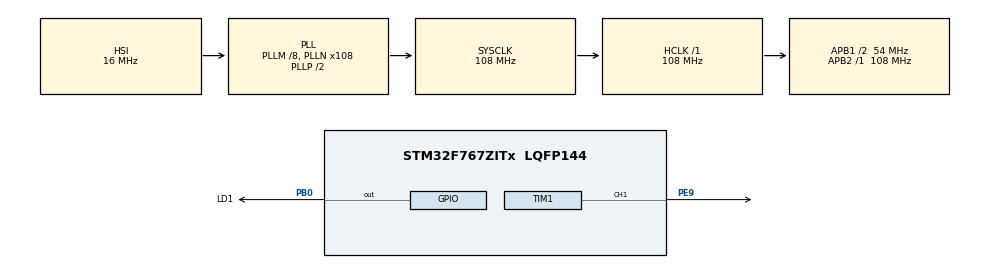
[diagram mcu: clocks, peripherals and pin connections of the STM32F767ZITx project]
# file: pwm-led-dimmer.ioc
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Mcu.Family=STM32F7
Mcu.Name=STM32F767ZITx
Mcu.Package=LQFP144
NVIC.PriorityGroup=NVIC_PRIORITYGROUP_4
PB0.GPIO_Label=LD1
PB0.Signal=GPIO_Output
PE9.Signal=S_TIM1_CH1
PH0/OSC_IN.Mode=HSE-External-Oscillator
PH0/OSC_IN.Signal=RCC_OSC_IN
PH1/OSC_OUT.Mode=HSE-External-Oscillator
PH1/OSC_OUT.Signal=RCC_OSC_OUT
ProjectManager.HeapSize=0x200
ProjectManager.StackSize=0x400
ProjectManager.TargetToolchain=STM32CubeIDE
RCC.48MHZClocksFreq_Value=24000000
RCC.AHBFreq_Value=108000000
RCC.APB1CLKDivider=RCC_HCLK_DIV2
RCC.APB1Freq_Value=54000000
RCC.APB1TimFreq_Value=108000000
RCC.APB2Freq_Value=108000000
RCC.APB2TimFreq_Value=108000000
RCC.CortexFreq_Value=108000000
RCC.HCLKFreq_Value=108000000
RCC.HSE_VALUE=8000000
RCC.HSI_VALUE=16000000
RCC.LSE_VALUE=32768
RCC.PLLM=8
RCC.PLLMUL=RCC_PLL_MUL9
RCC.PLLN=108
RCC.PRESCALERUSB=RCC_USBCLKSOURCE_PLL_DIV1_5
RCC.SYSCLKFreq_VALUE=108000000
RCC.SYSCLKSource=RCC_SYSCLKSOURCE_PLLCLK
RCC.SYSCLKSourceVirtual=RCC_SYSCLKSOURCE_PLLCLK
RCC.USBFreq_Value=108000000
RCC.VCOOutputFreq_Value=216000000
SH.S_TIM1_CH1.0=TIM1_CH1,PWM Generation1 CH1
TIM1.Channel-PWM\ Generation1\ CH1=TIM_CHANNEL_1
TIM1.Period=999
TIM1.Prescaler=108-1
VP_TIM1_VS_ClockSourceINT.Mode=Internal
board=NUCLEO-F767ZI

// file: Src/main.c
/* USER CODE BEGIN Header */
/**
  ******************************************************************************
  * @file           : main.c
  * @brief          : Main program body
  ******************************************************************************
  * @attention
  *
  * Copyright (c) 2025 STMicroelectronics.
  * All rights reserved.
  *
  * This software is licensed under terms that can be found in the LICENSE file
  * in the root directory of this software component.
  * If no LICENSE file comes with this software, it is provided AS-IS.
  *
  ******************************************************************************
  */
/* USER CODE END Header */
#include "main.h"

TIM_HandleTypeDef htim1;

/* USER CODE BEGIN PV */
uint16_t pwm_value = 0;
/* USER CODE END PV */

void SystemClock_Config(void);
static void MX_GPIO_Init(void);
static void MX_TIM1_Init(void);

int main(void)
{

  /* MCU Configuration--------------------------------------------------------*/

  /* Reset of all peripherals, Initializes the Flash interface and the Systick. */
  HAL_Init();

  /* Configure the system clock */
  SystemClock_Config();

  /* Initialize all configured peripherals */
  MX_GPIO_Init();
  MX_TIM1_Init();
  /* USER CODE BEGIN 2 */
  HAL_TIM_PWM_Start(&htim1, TIM_CHANNEL_1);
  /* USER CODE END 2 */

  /* Infinite loop */
  while (1)
  {

    /* USER CODE BEGIN 3 */
    // Fade up (increase brightness)
  for(pwm_value = 0; pwm_value <= 499; pwm_value++) {
      __HAL_TIM_SET_COMPARE(&htim1, TIM_CHANNEL_1, pwm_value);
      HAL_Delay(1); // Small delay to make the fade visible
  }

  // Fade down (decrease brightness)
  for(pwm_value = 499; pwm_value > 0; pwm_value--) {
      __HAL_TIM_SET_COMPARE(&htim1, TIM_CHANNEL_1, pwm_value);
      HAL_Delay(1);
  }

  }
  /* USER CODE END 3 */
}

void SystemClock_Config(void)
{
  RCC_OscInitTypeDef RCC_OscInitStruct = {0};
  RCC_ClkInitTypeDef RCC_ClkInitStruct = {0};

  /** Configure the main internal regulator output voltage
  */
  __HAL_RCC_PWR_CLK_ENABLE();
  __HAL_PWR_VOLTAGESCALING_CONFIG(PWR_REGULATOR_VOLTAGE_SCALE3);

  /** Initializes the RCC Oscillators according to the specified parameters
  * in the RCC_OscInitTypeDef structure.
  */
  RCC_OscInitStruct.OscillatorType = RCC_OSCILLATORTYPE_HSI;
  RCC_OscInitStruct.HSIState = RCC_HSI_ON;
  RCC_OscInitStruct.HSICalibrationValue = RCC_HSICALIBRATION_DEFAULT;
  RCC_OscInitStruct.PLL.PLLState = RCC_PLL_ON;
  RCC_OscInitStruct.PLL.PLLSource = RCC_PLLSOURCE_HSI;
  RCC_OscInitStruct.PLL.PLLM = 8;
  RCC_OscInitStruct.PLL.PLLN = 108;
  RCC_OscInitStruct.PLL.PLLP = RCC_PLLP_DIV2;
  RCC_OscInitStruct.PLL.PLLQ = 2;
  RCC_OscInitStruct.PLL.PLLR = 2;
  if (HAL_RCC_OscConfig(&RCC_OscInitStruct) != HAL_OK)
  {
    Error_Handler();
  }

  /** Activate the Over-Drive mode
  */
  if (HAL_PWREx_EnableOverDrive() != HAL_OK)
  {
    Error_Handler();
  }

  /** Initializes the CPU, AHB and APB buses clocks
  */
  RCC_ClkInitStruct.ClockType = RCC_CLOCKTYPE_HCLK|RCC_CLOCKTYPE_SYSCLK
                              |RCC_CLOCKTYPE_PCLK1|RCC_CLOCKTYPE_PCLK2;
  RCC_ClkInitStruct.SYSCLKSource = RCC_SYSCLKSOURCE_PLLCLK;
  RCC_ClkInitStruct.AHBCLKDivider = RCC_SYSCLK_DIV1;
  RCC_ClkInitStruct.APB1CLKDivider = RCC_HCLK_DIV2;
  RCC_ClkInitStruct.APB2CLKDivider = RCC_HCLK_DIV1;

  if (HAL_RCC_ClockConfig(&RCC_ClkInitStruct, FLASH_LATENCY_3) != HAL_OK)
  {
    Error_Handler();
  }
}

static void MX_TIM1_Init(void)
{

  TIM_ClockConfigTypeDef sClockSourceConfig = {0};
  TIM_MasterConfigTypeDef sMasterConfig = {0};
  TIM_OC_InitTypeDef sConfigOC = {0};
  TIM_BreakDeadTimeConfigTypeDef sBreakDeadTimeConfig = {0};

  htim1.Instance = TIM1;
  htim1.Init.Prescaler = 108-1;
  htim1.Init.CounterMode = TIM_COUNTERMODE_UP;
  htim1.Init.Period = 499;
  htim1.Init.ClockDivision = TIM_CLOCKDIVISION_DIV1;
  htim1.Init.RepetitionCounter = 0;
  htim1.Init.AutoReloadPreload = TIM_AUTORELOAD_PRELOAD_DISABLE;
  if (HAL_TIM_Base_Init(&htim1) != HAL_OK)
  {
    Error_Handler();
  }
  sClockSourceConfig.ClockSource = TIM_CLOCKSOURCE_INTERNAL;
  if (HAL_TIM_ConfigClockSource(&htim1, &sClockSourceConfig) != HAL_OK)
  {
    Error_Handler();
  }
  if (HAL_TIM_PWM_Init(&htim1) != HAL_OK)
  {
    Error_Handler();
  }
  sMasterConfig.MasterOutputTrigger = TIM_TRGO_RESET;
  sMasterConfig.MasterOutputTrigger2 = TIM_TRGO2_RESET;
  sMasterConfig.MasterSlaveMode = TIM_MASTERSLAVEMODE_DISABLE;
  if (HAL_TIMEx_MasterConfigSynchronization(&htim1, &sMasterConfig) != HAL_OK)
  {
    Error_Handler();
  }
  sConfigOC.OCMode = TIM_OCMODE_PWM1;
  sConfigOC.Pulse = 0;
  sConfigOC.OCPolarity = TIM_OCPOLARITY_HIGH;
  sConfigOC.OCNPolarity = TIM_OCNPOLARITY_HIGH;
  sConfigOC.OCFastMode = TIM_OCFAST_DISABLE;
  sConfigOC.OCIdleState = TIM_OCIDLESTATE_RESET;
  sConfigOC.OCNIdleState = TIM_OCNIDLESTATE_RESET;
  if (HAL_TIM_PWM_ConfigChannel(&htim1, &sConfigOC, TIM_CHANNEL_1) != HAL_OK)
  {
    Error_Handler();
  }
  sBreakDeadTimeConfig.OffStateRunMode = TIM_OSSR_DISABLE;
  sBreakDeadTimeConfig.OffStateIDLEMode = TIM_OSSI_DISABLE;
  sBreakDeadTimeConfig.LockLevel = TIM_LOCKLEVEL_OFF;
  sBreakDeadTimeConfig.DeadTime = 0;
  sBreakDeadTimeConfig.BreakState = TIM_BREAK_DISABLE;
  sBreakDeadTimeConfig.BreakPolarity = TIM_BREAKPOLARITY_HIGH;
  sBreakDeadTimeConfig.BreakFilter = 0;
  sBreakDeadTimeConfig.Break2State = TIM_BREAK2_DISABLE;
  sBreakDeadTimeConfig.Break2Polarity = TIM_BREAK2POLARITY_HIGH;
  sBreakDeadTimeConfig.Break2Filter = 0;
  sBreakDeadTimeConfig.AutomaticOutput = TIM_AUTOMATICOUTPUT_DISABLE;
  if (HAL_TIMEx_ConfigBreakDeadTime(&htim1, &sBreakDeadTimeConfig) != HAL_OK)
  {
    Error_Handler();
  }
  HAL_TIM_MspPostInit(&htim1);

}

static void MX_GPIO_Init(void)
{
  GPIO_InitTypeDef GPIO_InitStruct = {0};

  /* GPIO Ports Clock Enable */
  __HAL_RCC_GPIOH_CLK_ENABLE();
  __HAL_RCC_GPIOB_CLK_ENABLE();
  __HAL_RCC_GPIOE_CLK_ENABLE();

  /*Configure GPIO pin Output Level */
  HAL_GPIO_WritePin(LD1_GPIO_Port, LD1_Pin, GPIO_PIN_RESET);

  /*Configure GPIO pin : LD1_Pin */
  GPIO_InitStruct.Pin = LD1_Pin;
  GPIO_InitStruct.Mode = GPIO_MODE_OUTPUT_PP;
  GPIO_InitStruct.Pull = GPIO_NOPULL;
  GPIO_InitStruct.Speed = GPIO_SPEED_FREQ_LOW;
  HAL_GPIO_Init(LD1_GPIO_Port, &GPIO_InitStruct);

}

void Error_Handler(void)
{
  __disable_irq();
  while (1)
  {
  }
}
